# SF32LB57x register map
File version: 1.0
CPU: CM33 r0p1, little endian, MPU, FPU, 3 interrupt priority bits
Registers are 32-bit, read-write, reset 0x0 unless marked. A register's access mark holds for its fields unless they carry their own. Offsets are from the block's base; [hi:lo] are bit positions.

## DCMI
Base 0x50040000
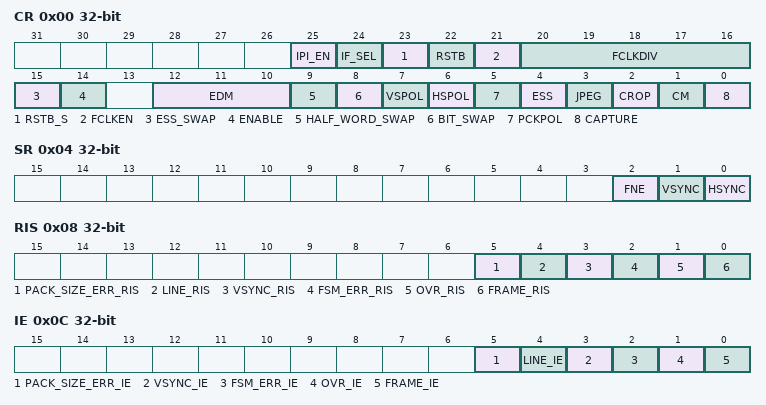
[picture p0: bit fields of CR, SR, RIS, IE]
0x00 CR
  [25] IPI_EN — not used
  [24] IF_SEL — 0x0:parallel interface ; 0x1: spi_interface
  [23] RSTB_S
  [22] RSTB
  [21] FCLKEN
  [20:16] FCLKDIV
  [15] ESS_SWAP
  [14] ENABLE — DCMI enable 0: DCMI disable 1: DCMI enable Note: The DCMI configuration registers should be programmed correctly before enabling this Bit
  [12:10] EDM — Extended data mode 000: Interface captures 8-bit data on every pixel clock 001: Interface captures 10-bit data on every pixel clock 010: Interface captures 12-bit data on every pixel clock 011: Interface captures 14-bit data on every pixel clock 100: Interface captures 16-bit data on every pixel clock Other value not support Note: Only used in DVP mode
  [9] HALF_WORD_SWAP — half-word swap 0: Not swap the two half-words within a word stored in RAM 1: Swap the two half-words within a word stored in RAM
  [8] BIT_SWAP — data bit swap 0: Sort the data according to the default most-significant-bit-first (MSB-first) order 1: Sort the data in order from least significant (LSB) to most significant bit (MSB).
  [7] VSPOL — Vertical synchrozation polarity This bit indicates the level on the DCMI_VSYNC pin when the data are not valid on the parallel interface 0:DCMI_VSYNC active low 1:DCMI_VSYNC active high Note: Only used in DVP mode
  [6] HSPOL — Horizontal synchrozation polarity This bit indicates the level on the DCMI_HSYNC pin when the data are not valid on the parallel interface 0:DCMI_HSYNC active low 1:DCMI_HSYNC active high Note: Only used in DVP mode
  [5] PCKPOL — pixel clock polarity This bit configures the capture edge of the pixel clock 0: Rising edge active 1: Falling edge active
  [4] ESS — Embedded synchronization select 0:Hardware synchronization data capture(frame/line start/stop) is synchronized with the DCMI_HSYNC/DCMI_VSYNC signals. 1: Embedded synchronization data capture is synchronized with syncchronization codes embedded in the data flow Note: Valid only for 8-bit parallel data. HSPOL/VSPOL are ignored when the ESS bit is set. This bit is disable in JPED mode
  [3] JPEG — JPEG format 0: Uncompressed video format 1: This bit is used for JPEG data transfers The DCMI_HSYNC signal is used as data enable. The crop and embedded synchronization features (Ess bit) cannot be used in this mode
  [2] CROP — crop feature : 0:The full image is captured. 1:Only the data inside the window specified by the crop register will be captured.
  [1] CM — capture mode 0 : Continuous grab mode -The received data are transferred into the destination memory through the DMA. 1: Snapshot mode(single frame) -Once actived, the interface waits for the start of frame and then transfers a single through the DMA.
  [0] CAPTURE — Capture enable 0: Capture disabled. 1: Capture enabled. Note: when capture mode equal 1, then it is necessary to manually configure the capture register to 0 and then to 1 to trigger the second capture
0x04 SR
  [2] FNE — FIFO not empty , This bit gived the status of the FIFO 1: FIFO contains valid data 0:FIFO empty
  [1] VSYNC
  [0] HSYNC
0x08 RIS
  [5] PACK_SIZE_ERR_RIS — This bit is set when in spi mode, one line data size configured in DCMI_SPI_CR is different from captured data in data flow. It is cleared by writing a '1' to the PACK_SIZE_ISC bit in DCMI_ICR.
  [4] LINE_RIS — This bit is set when the hsync changes from the inactive state to the active state. It is cleared by writing a '1' to the LINE_ISC bit in DCMI_ICR
  [3] VSYNC_RIS — This bit is set when the vsync changes from the inactive state to the active state. It is cleared by writing a '1' to the VSYNC_ISC bit in DCMI_ICR
  [2] FSM_ERR_RIS — Synchronization error raw interrupt status 0: No synchronization error detected 1: Embedded synchronization characters are not received in the correct order It is cleared by writing a '1' to the ERR_ICS bit in DCMI_ICR
  [1] OVR_RIS — Overrun raw interrupt status 0: No data buffer overrun occurred 1: A data buffer overrun occurred and the data FIFO is corrupted. This bit is clear by writing a '1' to the OVR_ISC bit in DCMI_ICR
  [0] FRAME_RIS — Capture complete raw interrupt status 0 : No new capture 1: A frame has been catured. This bit is cleared by writing a '1' to the FRAME_ISC bit in DCMI_ICR
0x0C IE
  [5] PACK_SIZE_ERR_IE — packet size error interrupt error enable
  [4] LINE_IE — line interrupt enable
  [3] VSYNC_IE — vsync interrupt enable
  [2] FSM_ERR_IE — Synchronization error raw interrupt enable
  [1] OVR_IE — Overrun raw interrupt enable
  [0] FRAME_IE — Capture complete raw interrupt enable
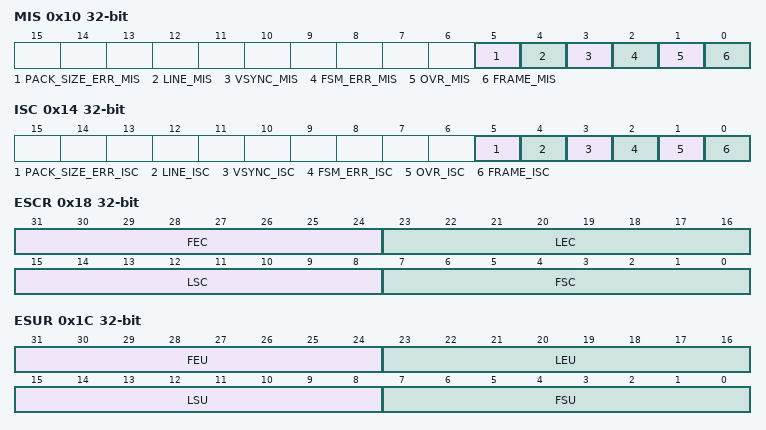
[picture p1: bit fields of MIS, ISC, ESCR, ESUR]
0x10 MIS
  [5] PACK_SIZE_ERR_MIS — packet size error masked interrupt status
  [4] LINE_MIS — line masked interrupt status
  [3] VSYNC_MIS — vsync masked interrupt status
  [2] FSM_ERR_MIS — synchronization error masked interrupt status
  [1] OVR_MIS — overrun masked interrupt status
  [0] FRAME_MIS — capture complete masked interrupt status
0x14 ISC
  [5] PACK_SIZE_ERR_ISC — packet size error interrupt status clear
  [4] LINE_ISC — line interrupt status clear
  [3] VSYNC_ISC — vertical synchronization interrupt status clear
  [2] FSM_ERR_ISC — synchronization error interrupt status clear
  [1] OVR_ISC — overrun interrupt status clear
  [0] FRAME_ISC — capture complete interrupt status clear
0x18 ESCR
  [31:24] FEC — Frame end delimiter code This byte specifies the code of the frame and delimiter. The code consists of 4 bytes in the form of 0xFF, 0x00, 0x00, FEC.
  [23:16] LEC — Line end delimiter code This byte specifies the code of the frame and delimiter. The code consists of 4 bytes in the form of 0xFF, 0x00, 0x00, LEC.
  [15:8] LSC — Line start delimiter code This byte specifies the code of the frame and delimiter. The code consists of 4 bytes in the form of 0xFF, 0x00, 0x00, LSC.
  [7:0] FSC — Frame start delimiter code This byte specifies the code of the frame and delimiter. The code consists of 4 bytes in the form of 0xFF, 0x00, 0x00, FSC.
0x1C ESUR
  [31:24] FEU — Frame end delimiter unmask This byte specifies the mask to be applied to the code of the frame and delimiter. 0: The corresponding bit in the FEC byte is masked while comparing the frame end delimiter with the received data 1: The corresponding bit in the FEC byte is compared while comparing the frame end delimiter with the received data
  [23:16] LEU — Line end delimiter unmask This byte specifies the mask to be applied to the code of the line and delimiter. 0: The corresponding bit in the LEC byte is masked while comparing the line end delimiter with the received data 1: The corresponding bit in the LEC byte is compared while comparing the line end delimiter with the received data
  [15:8] LSU — Line start delimiter unmask This byte specifies the mask to be applied to the code of the line start delimiter. 0: The corresponding bit in the LSC byte is masked while comparing the line start delimiter with the received data 1: The corresponding bit in the LSC byte is compared while comparing the line start delimiter with the received data
  [7:0] FSU — Frame start delimiter unmask This byte specifies the mask to be applied to the code of the frame start delimiter. 0: The corresponding bit in the FEC byte is masked while comparing the frame start delimiter with the received data 1: The corresponding bit in the FEC byte is compared while comparing the frame start delimiter with the received data
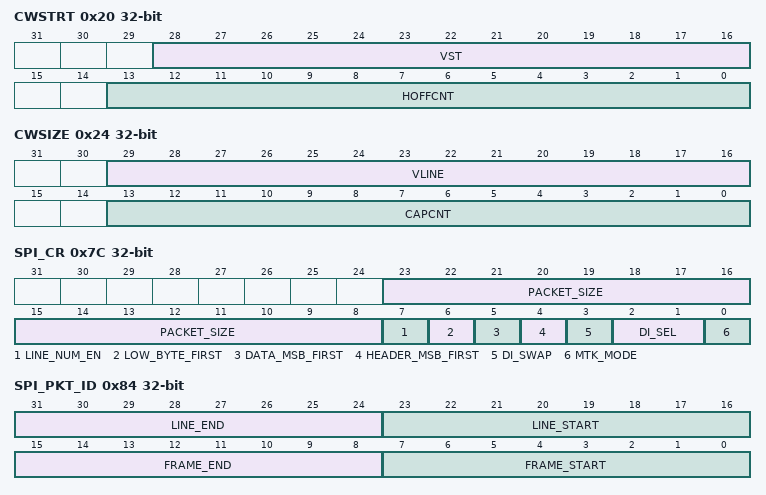
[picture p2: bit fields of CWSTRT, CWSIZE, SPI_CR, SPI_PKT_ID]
0x20 CWSTRT
  [28:16] VST — Vertical start line count The image capture starts with this line number. Previous line data are ignored.
  [13:0] HOFFCNT — Horizontial offset count This value gives the number of pixel clocks to count before starting a capture
0x24 CWSIZE
  [29:16] VLINE — Vertical line count This value gives the number of lines to be captured from the stating point
  [13:0] CAPCNT — Capture count This value gives the number of pixel clocks to be captured from the starting point on the same line. It value should cprresponds to word-aligned data for different widths of parallel interfaces
0x38 DR
  [31:0] DATA — The gigital camera Interface packages all the received data in 32-bit format before requesting a DMA transfer.
0x7C SPI_CR
  [23:8] PACKET_SIZE — In SPI MTK mode, this is used to check whether the received packet size matches the value in this register, if they are not equal, a packet_size_err interrupt will be triggered.
  [7] LINE_NUM_EN — Used in SPI MTK mode 0:don't display the received line number in the line_num field of spi_sr 1:display the received line number in the line_num field of spi_sr
  [6] LOW_BYTE_FIRST — when receiving line number and packet size 0: Received byte first is msb in a word 1: Received byte first is lsb in a word
  [5] DATA_MSB_FIRST — when reveive the data 0: the data received first is lsb 1:the data received first is msb
  [4] HEADER_MSB_FIRST — when detecting the sync word 0: the data received first is lsb 1:the data received first is msb
  [3] DI_SWAP — 0x0:Not swap the spi data at dcmi interface 0x1:swap the data at the dcmi interface
  [2:1] DI_SEL — 0x0: one-wire spi; 0x1: two-wire spi; 0x2: four-wire spi
  [0] MTK_MODE — 0x0: Not mtk mode 0x1: mtk mode
0x80 SPI_SYNC
  [23:0] WORD — sync word
0x84 SPI_PKT_ID
  [31:24] LINE_END — In SPI zhanxun mode is line start delimiter code. In SPI MTK mode is data packet demiliter code
  [23:16] LINE_START — line start delimiter code
  [15:8] FRAME_END — frame end delimiter code
  [7:0] FRAME_START — Frame start delimiter code
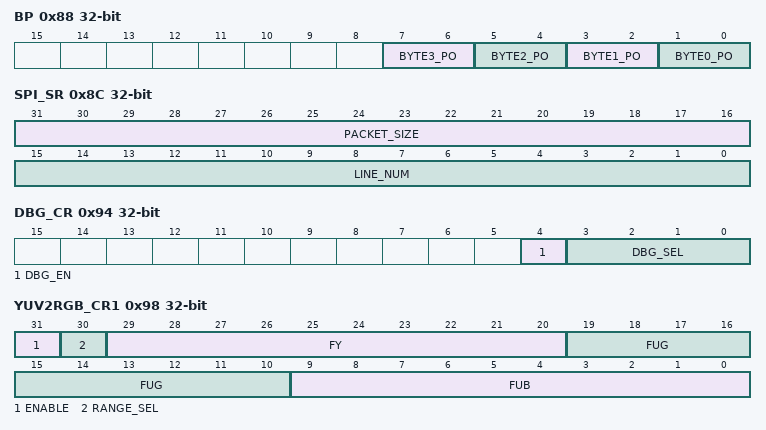
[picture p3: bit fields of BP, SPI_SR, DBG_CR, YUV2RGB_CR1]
0x88 BP
  [7:6] BYTE3_PO — Used to indicate the position within a word where the received fourth byte of data is placed 0x0: first byte 0x1:second byte 0x2: third byte 0x3: fourth byte
  [5:4] BYTE2_PO — Used to indicate the position within a word where the received third byte of data is placed 0x0: first byte 0x1:second byte 0x2: third byte 0x3: fourth byte
  [3:2] BYTE1_PO — Used to indicate the position within a word where the received second byte of data is placed 0x0: first byte 0x1:second byte 0x2: third byte 0x3: fourth byte
  [1:0] BYTE0_PO — Used to indicate the position within a word where the received first byte of data is placed 0x0: first byte 0x1:second byte 0x2: third byte 0x3: fourth byte
0x8C SPI_SR
  [31:16] PACKET_SIZE — Used to indicate received packet size
  [15:0] LINE_NUM — Used to indicate received line number
0x90 DMA_CR
  [4:0] DMA_NUM — Used to indicate how many words of data must be stored in the DCMI FIFO before requesting the DMA to transfer them. At the same time, the number of words transferred by the DMA each time must correspond to it.
0x94 DBG_CR
  [4] DBG_EN, [3:0] DBG_SEL
0x98 YUV2RGB_CR1
  [31] ENABLE — enable yuv422 to rgb565
  [30] RANGE_SEL
  [29:20] FY
  [19:10] FUG
  [9:0] FUB
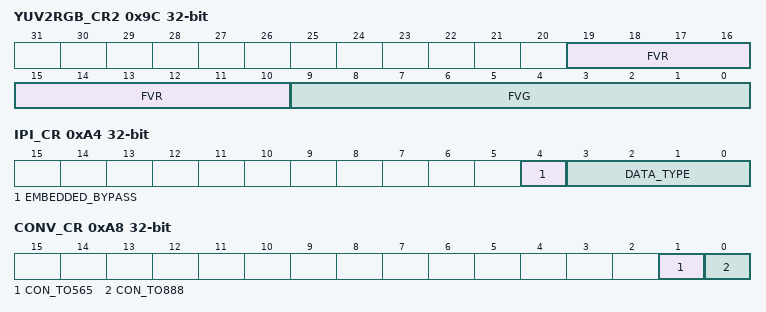
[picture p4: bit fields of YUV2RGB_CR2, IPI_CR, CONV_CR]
0x9C YUV2RGB_CR2
  [19:10] FVR, [9:0] FVG
0xA0 JPEG_BYTE
  [31:0] COUNT
0xA4 IPI_CR
  [4] EMBEDDED_BYPASS, [3:0] DATA_TYPE
0xA8 CONV_CR
  [1] CON_TO565
  [0] CON_TO888 — enable convert rgb565 to rgb888
0xAC FIFO_SR
  [8:0] FIFO_CNT
